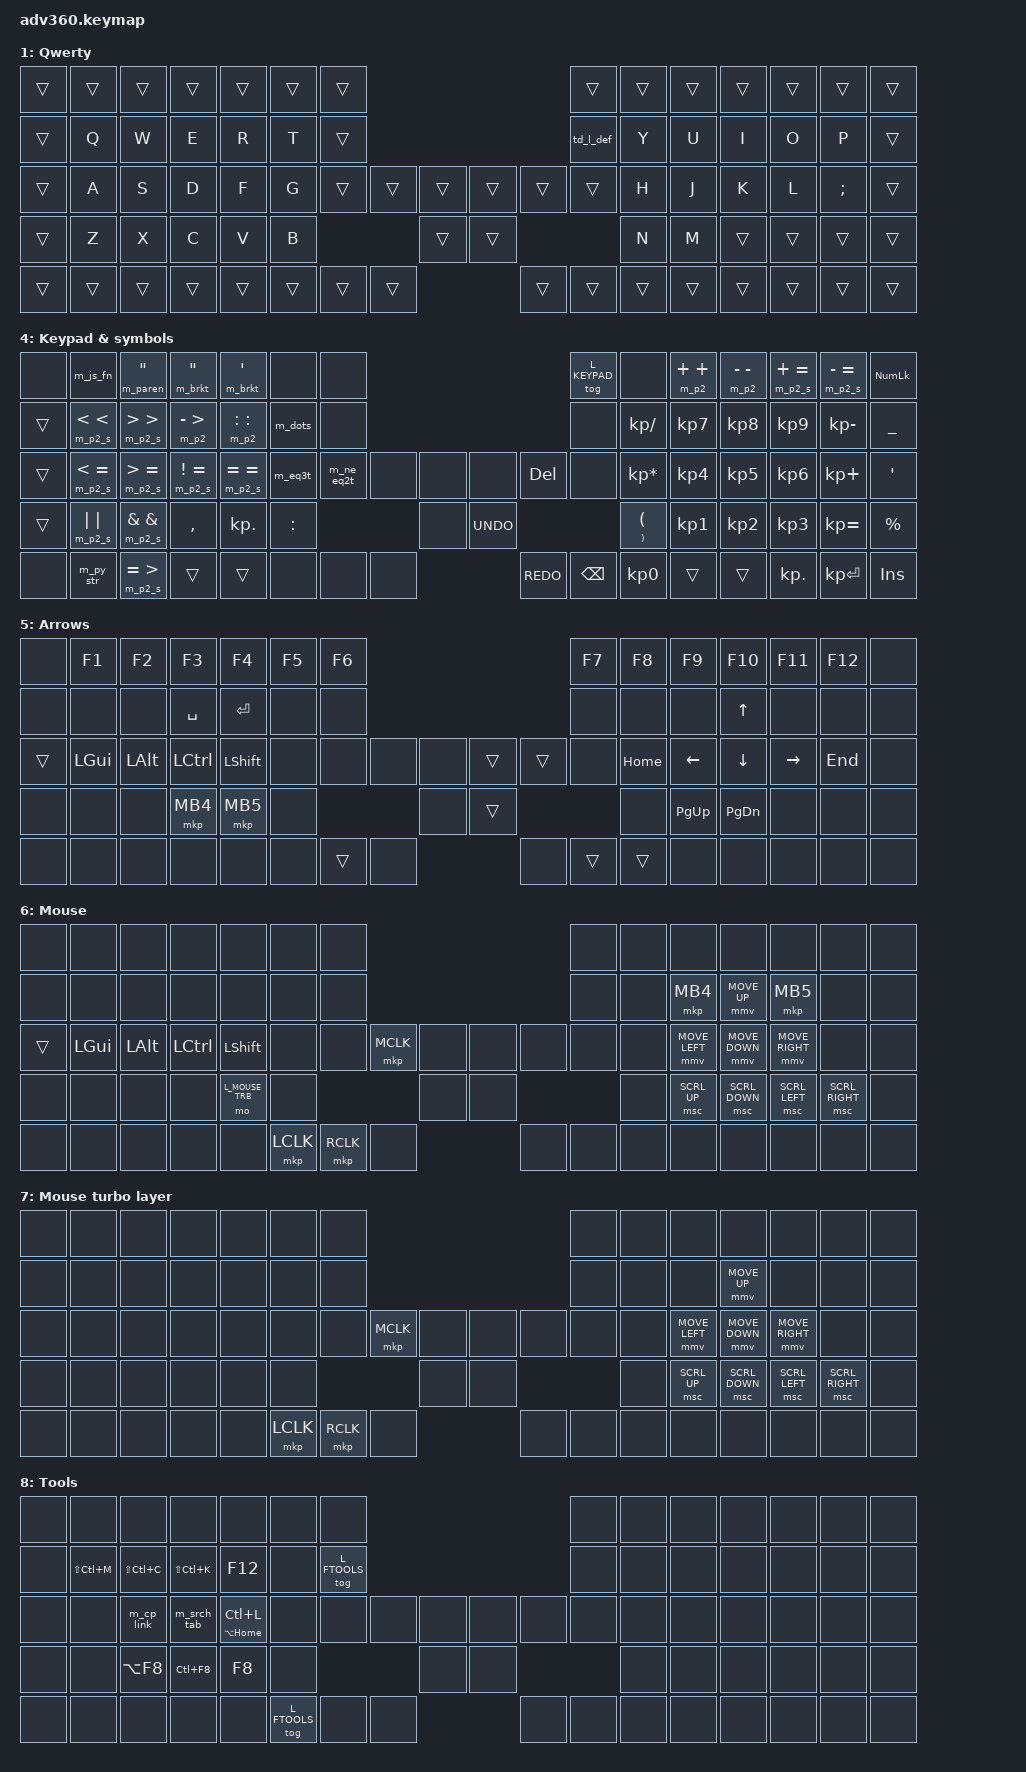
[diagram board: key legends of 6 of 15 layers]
#include <behaviors.dtsi>
#include <dt-bindings/zmk/keys.h>
#include <dt-bindings/zmk/bt.h>
#include <dt-bindings/zmk/rgb.h>
#include <dt-bindings/zmk/stp.h>
#include <dt-bindings/zmk/backlight.h>
#define ZMK_POINTING_DEFAULT_MOVE_VAL 1200 
#define ZMK_POINTING_DEFAULT_SCRL_VAL 20
#include <dt-bindings/zmk/pointing.h>
#include <input/processors.dtsi>

/* PREPROCESSOR */
// Constants
#define TAP_TERM_DEF 180
#define TAP_TERM_MFAST 130
#define TAP_TERM_FAST 150
#define TAP_TERM_SLOW 200
// Layers
#define L_DEFAULT    0
#define L_QWERTY     1
#define L_MAC        2
#define L_MEDIA      3
#define L_KEYPAD     4
#define L_ARROWS     5
#define L_MOUSE      6
#define L_MOUSE_TRB  7
#define L_FTOOLS     8
#define L_FTOOLS_MAC 9
#define L_HYPRLAND   10
#define L_HYPR_GR    11
#define L_AEROSPACE  12
#define L_APPS       13
#define L_EDITOR     14
// Macros
// - tap, hold, double tap
#define TD_A1(NAME, KP) \
    NAME: NAME { \
        compatible = "zmk,behavior-tap-dance"; \
        #binding-cells = <0>; \
        bindings = <&kp KP>; \
    }
#define TD_A1_DT_TOG_LYR(NAME, LAYER) \
    NAME: NAME { \
        compatible = "zmk,behavior-tap-dance"; \
        #binding-cells = <0>; \
        tapping-term-ms = <TAP_TERM_DEF>; \
        bindings = <&none>, <&tog LAYER>; \
    }
#define TD_A1_DT_KP(NAME, KP ) \
    NAME: NAME { \
        compatible = "zmk,behavior-tap-dance"; \
        #binding-cells = <0>; \
        tapping-term-ms = <TAP_TERM_DEF>; \
        bindings = <&none>, <&kp KP>; \
    }
#define TD_A1_DT_TO_LYR(NAME, LAYER) \
    NAME: NAME { \
        compatible = "zmk,behavior-tap-dance"; \
        #binding-cells = <0>; \
        tapping-term-ms = <TAP_TERM_DEF>; \
        bindings = <&none>, <&to LAYER>; \
    }
#define TD_A2(NAME, TAP, D_TAP) \
    NAME: NAME { \
        compatible = "zmk,behavior-tap-dance"; \
        #binding-cells = <0>; \
        tapping-term-ms = <TAP_TERM_DEF>; \
        bindings = <&kp TAP>, <&kp D_TAP>; \
    }
#define TD_A3(NAME, TAP, HOLD, D_TAP) \
    NAME: NAME { \
        compatible = "zmk,behavior-tap-dance"; \
        #binding-cells = <0>; \
        tapping-term-ms = <TAP_TERM_DEF>; \
        bindings = <&ht_dfn_mfst HOLD TAP>, <&kp D_TAP>; \
    }
#define TD_A4(NAME, TAP, HOLD, D_TAP, T_TAP) \
    NAME: NAME { \
        compatible = "zmk,behavior-tap-dance"; \
        #binding-cells = <0>; \
        tapping-term-ms = <TAP_TERM_SLOW>; \
        bindings = <&ht_dfn_mfst HOLD TAP>, <&kp D_TAP>, <&kp T_TAP>; \
    }
#define TD_SL_TOG(NAME, LAYER) \
    NAME: NAME { \
        compatible = "zmk,behavior-tap-dance"; \
        #binding-cells = <0>; \
        tapping-term-ms = <TAP_TERM_DEF>; \
        bindings = <&sl LAYER>, <&tog LAYER>; \
    }

/* DEFAULT BEHAVIORS */
&mt { // Mod-Tap
    tapping-term-ms = <TAP_TERM_DEF>;
};
&lt { // Layer-Tap
    tapping-term-ms = <TAP_TERM_DEF>;
};
&sk { // Sticky key
    release-after-ms = <1000>;
};
&sl { // Sticky layer
    release-after-ms = <1500>;
    /delete-property/ quick-release;
};
&caps_word {
    continue-list = <UNDERSCORE MINUS BACKSPACE DELETE>;
};
&mmv {
    time-to-max-speed-ms = <400>;
    delay-ms = <0>;
};
&msc {
    delay-ms = <0>;
};
/* CONFIG */
/ {
    behaviors {
        // Custom
        esc_ent: mod_morph_escape_enter {
            compatible = "zmk,behavior-mod-morph";
            #binding-cells = <0>;
            bindings = <&kp ESC>, <&kp ENTER>;
            mods = <MOD_LCTL>;
        };
        skq: sticky_key_quick_release {
            compatible = "zmk,behavior-sticky-key";
            #binding-cells = <1>;
            bindings = <&kp>;
            release-after-ms = <1500>;
            quick-release;
            ignore-modifiers;
        };
        hrm: ht_home_row_mods {
            compatible = "zmk,behavior-hold-tap";
            #binding-cells = <2>;
            /* flavor = "balanced"; */
            flavor = "tap-preferred";
            require-prior-idle-ms = <135>;
            tapping-term-ms = <TAP_TERM_DEF>;
            quick-tap-ms = <150>;
            hold-while-undecided;
            retro-tap;
            bindings = <&kp>, <&kp>;
        };
        ht_cl: ht_cluster_layer {
            compatible = "zmk,behavior-hold-tap";
            #binding-cells = <2>;
            flavor = "hold-preferred"; 
            tapping-term-ms = <TAP_TERM_SLOW>;
            quick-tap-ms = <175>;     
            /* retro-tap;           */
            bindings = <&mo>, <&kp>;
        };
        ht_cl_tp: ht_cluster_layer_tap_preferred {
            compatible = "zmk,behavior-hold-tap";
            #binding-cells = <2>;
            flavor = "tap-preferred"; 
            tapping-term-ms = <TAP_TERM_DEF>;
            quick-tap-ms = <TAP_TERM_DEF>;     
            require-prior-idle-ms = <160>;
            retro-tap;          
            bindings = <&mo>, <&kp>;
        };
        test_lp: test_layer_press {
            compatible = "zmk,behavior-hold-tap";
            #binding-cells = <2>;
            flavor = "hold-preferred";
            tapping-term-ms = <200>;
            quick-tap-ms = <175>;      
            retro-tap;                 
            bindings = <&mo>, <&kp>;   
        };
        ht_dfn_mfst: ht_dual_function_mega_fast {
            compatible = "zmk,behavior-hold-tap";
            #binding-cells = <2>;
            flavor = "tap-preferred"; 
            tapping-term-ms = <TAP_TERM_MFAST>;
            bindings = <&kp>, <&kp>;
        };
        ht_mo_sl: ht_momentary_sticky_layer { 
            compatible = "zmk,behavior-hold-tap";
            #binding-cells = <2>;
            flavor = "hold-preferred";
            tapping-term-ms = <TAP_TERM_FAST>;
            bindings = <&mo>, <&sl>; 
        };
        ht_tog_sl: ht_toggle_sticky_layer { 
            compatible = "zmk,behavior-hold-tap";
            #binding-cells = <2>;
            flavor = "hold-preferred";
            tapping-term-ms = <TAP_TERM_FAST>;
            bindings = <&tog>, <&sl>; 
        };
        ht_mo_tog: ht_momentary_toggle_layer { 
            compatible = "zmk,behavior-hold-tap";
            #binding-cells = <2>;
            flavor = "hold-preferred";
            tapping-term-ms = <TAP_TERM_FAST>;
            bindings = <&mo>, <&tog>; 
        };
        cw_caps: caps_word_hold_tap {
            compatible = "zmk,behavior-hold-tap";
            #binding-cells = <2>;
            flavor = "tap-preferred";
            tapping-term-ms = <TAP_TERM_MFAST>;
            quick-tap-ms = <0>;
            bindings = <&kp>, <&caps_word>; 
        };
        // - Keyboard layout (qwerty/mac) switch on hold and double tap 
        to_hold_tap: to_hold_tap {
            compatible = "zmk,behavior-hold-tap";
            #binding-cells = <2>;
            flavor = "tap-preferred";
            tapping-term-ms = <TAP_TERM_DEF>;
            bindings = <&to>, <&none>;
        };
        td_layout: td_change_layout {
            compatible = "zmk,behavior-tap-dance";
            #binding-cells = <0>;
            tapping-term-ms = <TAP_TERM_DEF>;
            bindings = <&to_hold_tap L_MAC 0>, <&to L_QWERTY>; 
        };
        td_bootloader: td_bootloader {
            compatible = "zmk,behavior-tap-dance";
            #binding-cells = <0>;
            tapping-term-ms = <TAP_TERM_DEF>;
            bindings = <&none>, <&bootloader>; 
        };
        td_bt_cl: td_bluetooth_clear {
            compatible = "zmk,behavior-tap-dance";
            #binding-cells = <0>;
            tapping-term-ms = <TAP_TERM_DEF>;
            bindings = <&none>, <&bt BT_CLR>; 
        };
        td_bt_cl_all: td_bluetooth_clear_all {
            compatible = "zmk,behavior-tap-dance";
            #binding-cells = <0>;
            tapping-term-ms = <TAP_TERM_DEF>;
            bindings = <&none>, <&bt BT_CLR_ALL>; 
        };
        // tap-dance
        TD_A1_DT_TOG_LYR(td_keypad, L_KEYPAD); // toggle keypad layer on double tap
        TD_A1_DT_TO_LYR(td_l_def, L_DEFAULT); // toggle default layer on double tap
        TD_A1_DT_KP(td_sleep_lnx, LG(LS(LA(L)))); // sleep system on Linux
        TD_A1_DT_KP(td_sleep_mac, LC(LA(C_EJECT))); // sleep system on MacOS
        TD_A3(td_e_methods, LS(LC(D)), LC(I), LC(O)); // editor, methods
        TD_A3(td_e_refactor, LS(F6), LC(F6), F6); // editor, refactor
        TD_A3(td_e_sur_life, LC(LA(J)), LS(LA(T)), LC(J)); // editor, surround/live template
        TD_A3(td_e_f_expand, LC(EQUAL), LC(LA(EQUAL)), LS(LC(EQUAL))); // editor, fold expand
        TD_A3(td_e_f_collapse, LC(MINUS), LC(LA(MINUS)), LS(LC(MINUS))); // editor, fold collapse
        TD_A3(td_tmac_info, LG(LA(I)), LG(I), LG(J)); // mac, tools, files info
        TD_A4(td_e_bookmarks, LS(LC(LA(RIGHT_BRACKET))), F11, LS(LC(LA(LEFT_BRACKET))), LS(LC(F11))); // editor, bookmarks
        TD_A4(td_a4_h_res, LG(R), LG(LC(R)), LG(LA(R)), LG(LC(LA(R)))); // hyprland, resize window
        TD_A4(td_breakpoint, LC(F8), LS(LC(F8)), LS(LC(F3)), LS(LC(LA(F8)))); // editor, breakpoints
        TD_SL_TOG(td_hypr, L_HYPRLAND); // hyprland layer activation
        TD_SL_TOG(td_aerospace, L_AEROSPACE); // aerospace layer activation
        // macros
        m_pc: macro_switch_to_pc {
            compatible = "zmk,behavior-macro";
            #binding-cells = <0>; 
            bindings =
                <&to L_DEFAULT>,
                <&bt BT_SEL 0>;
        };
        m_mac: macro_switch_to_mac {
            compatible = "zmk,behavior-macro";
            #binding-cells = <0>; 
            bindings =
                <&to L_MAC>,
                <&bt BT_SEL 1>;
        };
        m_p2: macro_two_param {
            compatible = "zmk,behavior-macro-two-param";
            #binding-cells = <2>; 
            bindings =
                <&macro_param_1to1>,
                <&macro_tap &kp MACRO_PLACEHOLDER>,
                <&macro_param_2to1>,
                <&macro_tap &kp MACRO_PLACEHOLDER>;
        };
        m_p2_s: macro_two_param_with_space {
            compatible = "zmk,behavior-macro-two-param";
            #binding-cells = <2>; 
            bindings =
                <&macro_param_1to1>,
                <&macro_tap &kp MACRO_PLACEHOLDER>,
                <&macro_param_2to1>,
                <&macro_tap &kp MACRO_PLACEHOLDER>,
                <&macro_tap &kp SPACE>;
        };
        m_brkt: macro_brackets_left_left {
            compatible = "zmk,behavior-macro-one-param";
            #binding-cells = <1>; 
            bindings =
                <&macro_tap &kp LEFT_BRACKET>,               
                <&macro_param_1to1>,
                <&macro_tap &kp MACRO_PLACEHOLDER>,
                <&macro_param_1to1>,
                <&macro_tap &kp MACRO_PLACEHOLDER>,
                <&macro_tap &kp RIGHT_BRACKET>,
                <&macro_tap &kp LEFT_ARROW &kp LEFT_ARROW>;
        };
        m_paren: macro_parenthesis_left_left {
            compatible = "zmk,behavior-macro-one-param";
            #binding-cells = <1>; 
            bindings =
                <&macro_tap &kp LEFT_PARENTHESIS>,               
                <&macro_param_1to1>,
                <&macro_tap &kp MACRO_PLACEHOLDER>,
                <&macro_param_1to1>,
                <&macro_tap &kp MACRO_PLACEHOLDER>,
                <&macro_tap &kp RIGHT_PARENTHESIS>,
                <&macro_tap &kp LEFT_ARROW &kp LEFT_ARROW>;
        };
        m_js_fn: macro_js_anon_function {
            compatible = "zmk,behavior-macro";
            #binding-cells = <0>; 
            bindings =
                <&macro_tap &kp LEFT_PARENTHESIS &kp RIGHT_PARENTHESIS>,               
                <&macro_tap &kp SPACE &kp EQUAL &kp GREATER_THAN>;
        };
        m_py_str: macro_python_string_param {
            compatible = "zmk,behavior-macro";
            #binding-cells = <0>; 
            bindings =
                <&macro_tap &kp DOLLAR>,
                <&macro_tap &kp LEFT_BRACE &kp RIGHT_BRACE>,
                <&macro_tap &kp LEFT_ARROW>;
        };
        m_dots: macro_triple_dots {
            compatible = "zmk,behavior-macro";
            #binding-cells = <0>; 
            bindings = <&macro_tap &kp DOT &kp DOT &kp DOT>;
        };
        m_eq3t: macro_eq_eq_eq {
            compatible = "zmk,behavior-macro";
            #binding-cells = <0>; 
            bindings = <&macro_tap &kp EQUAL &kp EQUAL &kp EQUAL &kp SPACE>;
        };
        m_ne_eq2t: macro_ne_eq_eq {
            compatible = "zmk,behavior-macro";
            #binding-cells = <0>; 
            bindings = <&macro_tap &kp EXCL &kp EQUAL &kp EQUAL &kp SPACE>;
        };
        m_cp_link: macro_copy_link {
            compatible = "zmk,behavior-macro";
            #binding-cells = <0>; 
            bindings = <&macro_tap &kp LC(L) &kp LC(C) &kp ESC &kp ESC>;
        };
        m_cp_link_m: macro_copy_link_mac {
            compatible = "zmk,behavior-macro";
            #binding-cells = <0>; 
            bindings = <&macro_tap &kp LC(L) &kp LG(C) &kp ESC &kp ESC>;
        };
        m_srch_tab: macro_search_tab {
            compatible = "zmk,behavior-macro";
            #binding-cells = <0>; 
            bindings = <&macro_tap &kp LC(L) &kp PERCENT &kp SPACE>;
        };
    };

  /* KEYMAP */
  keymap {
    compatible = "zmk,keymap";
    default_layer { 
      display-name = "Base";
      bindings = <
  &kp GRAVE    &kp N1     &kp N2            &kp N3     &kp N4      &kp N5   &kp PSCRN                                                                                                                                                                 &td_keypad   &kp N6   &kp N7   &kp N8      &kp N9     &kp N0     &kp EQUAL
  &kp TAB      &kp Q      &kp W             &kp F      &kp P       &kp B    &ht_tog_sl L_FTOOLS L_FTOOLS                                                                                                                                              &td_layout   &kp J    &kp L    &kp U       &kp Y      &kp SEMI   &kp MINUS
  &kp ESC      &kp A      &kp R             &kp S      &kp T       &kp G    &ht_dfn_mfst LG(LC(LA(LEFT))) LG(LC(LA(RIGHT)))                          &kp LCTRL             &kp LALT   &sk LALT      &sk RCTRL                                         &none        &kp M    &kp N    &kp E       &kp I      &kp O      &kp SQT
  &kp LSHFT    &kp Z      &kp X             &kp C      &kp D       &kp V                                                                                                   &kp LGUI   &sk RGUI                                                                     &kp K    &kp H    &kp COMMA   &kp DOT    &kp FSLH   &kp RSHFT
  &sl L_APPS   &kp BSLH   &cw_caps CAPS 0   &kp LEFT   &kp RIGHT                                                              &ht_cl L_ARROWS BSPC   &ht_cl L_KEYPAD DEL   &td_hypr   &mo L_MEDIA   &ht_cl L_EDITOR ENTER   &ht_cl_tp L_MOUSE SPACE                         &kp UP   &kp DOWN    &kp LBKT   &kp RBKT   &ht_dfn_mfst LG(LC(L)) LG(LS(L))
//    ┌─────────┬───┬──────────┬──────┬──────┬───┬──────────────┐                                                                                  ┌───────────────┬───┬────┬──────┬───┬───┬──────┐
//    │    `    │ 1 │    2     │  3   │  4   │ 5 │     pscr     │                                                                                  │  tog Keypad   │ 6 │ 7  │  8   │ 9 │ 0 │  =   │
//    ├─────────┼───┼──────────┼──────┼──────┼───┼──────────────┤                                                                                  ├───────────────┼───┼────┼──────┼───┼───┼──────┤
//    │   tab   │ Q │    W     │  F   │  P   │ B │ tog sl Tools │                                                                                  │ to Qwerty/Mac │ J │ L  │  U   │ Y │ ; │  -   │
//    ├─────────┼───┼──────────┼──────┼──────┼───┼──────────────┤             ┌────────────┬─────────────┬────────────┬──────────────┐             ├───────────────┼───┼────┼──────┼───┼───┼──────┤
//    │   esc   │ A │    R     │  S   │  T   │ G │  < worksp >  │             │    lctl    │    lalt     │  &sk lalt  │   &sk rctl   │             │               │ M │ N  │  E   │ I │ O │  '   │
//    ├─────────┼───┼──────────┼──────┼──────┼───┼──────────────┘             └────────────┼─────────────┼────────────┼──────────────┘             └───────────────┼───┼────┼──────┼───┼───┼──────┤
//    │  lsft   │ Z │    X     │  C   │  D   │ V │                                         │    lgui     │  &sk rgui  │                                            │ K │ H  │  ,   │ . │ / │ rsft │
//    ├─────────┼───┼──────────┼──────┼──────┼───┘              ┌─────────────┬────────────┼─────────────┼────────────┼──────────────┬─────────────┐               └───┼────┼──────┼───┼───┼──────┤
//    │ sl Apps │ \ │ caps duo │ left │ rght │                  │ bspc/Arrows │ del/Keypad │ td Hyprland │ mo L_MEDIA │ enter/Editor │ space/Mouse │                   │ up │ down │ [ │ ] │ lang │
//    └─────────┴───┴──────────┴──────┴──────┘                  └─────────────┴────────────┴─────────────┴────────────┴──────────────┴─────────────┘                   └────┴──────┴───┴───┴──────┘
      >;
    };
    qwerty { 
      display-name = "Qwerty";
      bindings = <
  &trans   &trans   &trans   &trans   &trans   &trans   &trans                                                         &trans      &trans   &trans   &trans   &trans   &trans     &trans
  &trans   &kp Q    &kp W    &kp E    &kp R    &kp T    &trans                                                         &td_l_def   &kp Y    &kp U    &kp I    &kp O    &kp P      &trans
  &trans   &kp A    &kp S    &kp D    &kp F    &kp G    &trans            &trans   &trans   &trans   &trans            &trans      &kp H    &kp J    &kp K    &kp L    &kp SEMI   &trans
  &trans   &kp Z    &kp X    &kp C    &kp V    &kp B                               &trans   &trans                                 &kp N    &kp M    &trans   &trans   &trans     &trans
  &trans   &trans   &trans   &trans   &trans                     &trans   &trans   &trans   &trans   &trans   &trans                        &trans   &trans   &trans   &trans     &trans
//    ┌───┬───┬───┬───┬───┬───┬───┐                       ┌────────────┬───┬───┬───┬───┬───┬───┐
//    │ & │ & │ & │ & │ & │ & │ & │                       │     &      │ & │ & │ & │ & │ & │ & │
//    ├───┼───┼───┼───┼───┼───┼───┤                       ├────────────┼───┼───┼───┼───┼───┼───┤
//    │ & │ Q │ W │ E │ R │ T │ & │                       │ to Default │ Y │ U │ I │ O │ P │ & │
//    ├───┼───┼───┼───┼───┼───┼───┤   ┌───┬───┬───┬───┐   ├────────────┼───┼───┼───┼───┼───┼───┤
//    │ & │ A │ S │ D │ F │ G │ & │   │ & │ & │ & │ & │   │     &      │ H │ J │ K │ L │ ; │ & │
//    ├───┼───┼───┼───┼───┼───┼───┘   └───┼───┼───┼───┘   └────────────┼───┼───┼───┼───┼───┼───┤
//    │ & │ Z │ X │ C │ V │ B │           │ & │ & │                    │ N │ M │ & │ & │ & │ & │
//    ├───┼───┼───┼───┼───┼───┘   ┌───┬───┼───┼───┼───┬───┐            └───┼───┼───┼───┼───┼───┤
//    │ & │ & │ & │ & │ & │       │ & │ & │ & │ & │ & │ & │                │ & │ & │ & │ & │ & │
//    └───┴───┴───┴───┴───┘       └───┴───┴───┴───┴───┴───┘                └───┴───┴───┴───┴───┘
      >;
    };
    mac { 
      display-name = "MacOS";
      bindings = <
  &trans    &trans   &trans   &trans   &trans   &trans   &ht_dfn_mfst LG(LS(N3)) LG(LS(N4))                                                                             &trans          &trans   &trans   &trans   &trans   &trans   &trans
  &trans    &trans   &trans   &trans   &trans   &trans   &ht_tog_sl L_FTOOLS_MAC L_FTOOLS_MAC                                                                           &td_l_def       &trans   &trans   &trans   &trans   &trans   &trans
  &kp ESC   &trans   &trans   &trans   &trans   &trans   &ht_dfn_mfst LG(LS(LC(W))) LG(LC(LA(W)))            &sk LGUI   &trans          &trans      &sk RGUI            &kp LC(SPACE)   &trans   &trans   &trans   &trans   &trans   &trans
  &trans    &trans   &trans   &trans   &trans   &trans                                                                  &sk LCTRL       &sk RCTRL                                       &trans   &trans   &trans   &trans   &trans   &trans
  &trans    &trans   &trans   &trans   &trans                                                       &trans   &trans     &td_aerospace   &trans      &trans     &trans                            &trans   &trans   &trans   &trans   &kp LG(SPACE)
//    ┌─────┬───┬───┬───┬───┬───┬──────────────────┐                                                       ┌────────────┬───┬───┬───┬───┬───┬──────┐
//    │  &  │ & │ & │ & │ & │ & │    screenshot    │                                                       │     &      │ & │ & │ & │ & │ & │  &   │
//    ├─────┼───┼───┼───┼───┼───┼──────────────────┤                                                       ├────────────┼───┼───┼───┼───┼───┼──────┤
//    │  &  │ & │ & │ & │ & │ & │ tog sl Tools mac │                                                       │ to Default │ & │ & │ & │ & │ & │  &   │
//    ├─────┼───┼───┼───┼───┼───┼──────────────────┤   ┌──────────┬──────────────┬──────────┬──────────┐   ├────────────┼───┼───┼───┼───┼───┼──────┤
//    │ esc │ & │ & │ & │ & │ & │    < worksp >    │   │ &sk lgui │      &       │    &     │ &sk rgui │   │   search   │ & │ & │ & │ & │ & │  &   │
//    ├─────┼───┼───┼───┼───┼───┼──────────────────┘   └──────────┼──────────────┼──────────┼──────────┘   └────────────┼───┼───┼───┼───┼───┼──────┤
//    │  &  │ & │ & │ & │ & │ & │                                 │   &sk lctl   │ &sk rctl │                           │ & │ & │ & │ & │ & │  &   │
//    ├─────┼───┼───┼───┼───┼───┘                  ┌───┬──────────┼──────────────┼──────────┼──────────┬───┐            └───┼───┼───┼───┼───┼──────┤
//    │  &  │ & │ & │ & │ & │                      │ & │    &     │ td Aerospace │    &     │    &     │ & │                │ & │ & │ & │ & │ lang │
//    └─────┴───┴───┴───┴───┘                      └───┴──────────┴──────────────┴──────────┴──────────┴───┘                └───┴───┴───┴───┴──────┘
      >;
    };
    media { 
      display-name = "Media";
      bindings = <
  &none            &m_pc   &m_mac          &bt BT_SEL 2   &bt BT_SEL 3    &bt BT_SEL 4   &none                                                                                     &none           &none                   &none                   &none               &none               &none   &td_bt_cl
  &none            &none   &none           &none          &none           &none          &none                                                                                     &td_sleep_mac   &kp LG(LC(Q))           &kp LG(LS(LC(LA(O))))   &kp LG(LS(LA(O)))   &kp LG(LS(LC(O)))   &none   &td_bt_cl_all
  &studio_unlock   &none   &kp C_BRI_DEC   &none          &kp C_BRI_INC   &none          &none                &bl BL_TOG   &rgb_ug RGB_TOG   &none   &none                         &td_sleep_lnx   &kp LG(LS(LC(LA(L))))   &kp C_VOL_DN            &kp C_MUTE          &kp C_VOL_UP        &none   &none
  &stp STP_BAT     &none   &none           &none          &none           &none                                            &none             &none                                                 &none                   &kp C_PREV              &kp C_PLAY_PAUSE    &kp C_NEXT          &none   &none
  &td_bootloader   &none   &none           &none          &none                                  &bl BL_DEC   &bl BL_INC   &none             &none   &kp C_VOL_DN   &kp C_VOL_UP                                           &none                   &none               &none               &none   &td_bootloader
//    ┌────────────────┬───────┬────────┬──────────┬──────────┬──────────┬─────┐                                                 ┌───────────────┬──────────┬──────────┬────────────┬──────┬─────┬────────────────┐
//    │                │ &m_pc │ &m_mac │ bt_sel 2 │ bt_sel 3 │ bt_sel 4 │     │                                                 │               │          │          │            │      │     │   &td_bt_cl    │
//    ├────────────────┼───────┼────────┼──────────┼──────────┼──────────┼─────┤                                                 ├───────────────┼──────────┼──────────┼────────────┼──────┼─────┼────────────────┤
//    │                │       │        │          │          │          │     │                                                 │ &td_sleep_mac │ lock mac │ speakers │ headphones │ hdmi │     │ &td_bt_cl_all  │
//    ├────────────────┼───────┼────────┼──────────┼──────────┼──────────┼─────┤         ┌─────────┬─────────┬─────┬──────┐      ├───────────────┼──────────┼──────────┼────────────┼──────┼─────┼────────────────┤
//    │ &studio_unlock │       │  bri-  │          │   bri+   │          │     │         │ bl_ tog │ ug_ tog │     │      │      │ &td_sleep_lnx │   lock   │   vold   │    mute    │ volu │     │                │
//    ├────────────────┼───────┼────────┼──────────┼──────────┼──────────┼─────┘         └─────────┼─────────┼─────┼──────┘      └───────────────┼──────────┼──────────┼────────────┼──────┼─────┼────────────────┤
//    │    bat lvl     │       │        │          │          │          │                         │         │     │                             │          │   prev   │    play    │ next │     │                │
//    ├────────────────┼───────┼────────┼──────────┼──────────┼──────────┘     ┌─────────┬─────────┼─────────┼─────┼──────┬──────┐               └──────────┼──────────┼────────────┼──────┼─────┼────────────────┤
//    │ &td_bootloader │       │        │          │          │                │ bl_ br- │ bl_ br+ │         │     │ vold │ volu │                          │          │            │      │     │ &td_bootloader │
//    └────────────────┴───────┴────────┴──────────┴──────────┘                └─────────┴─────────┴─────────┴─────┴──────┴──────┘                          └──────────┴────────────┴──────┴─────┴────────────────┘
      >;
    };
    keypad { 
      display-name = "Keypad & symbols";
      bindings = <
  &none    &m_js_fn            &m_paren DOUBLE_QUOTES   &m_brkt DOUBLE_QUOTES   &m_brkt SINGLE_QUOTE   &none       &none                                                                         &tog L_KEYPAD   &none                    &m_p2 PLUS PLUS   &m_p2 MINUS MINUS   &m_p2_s PLUS EQUAL   &m_p2_s MINUS EQUAL   &kp KP_NUMLOCK
  &trans   &m_p2_s LT LT       &m_p2_s GT GT            &m_p2 MINUS GT          &m_p2 COLON COLON      &m_dots     &none                                                                         &none           &kp KP_DIVIDE            &kp KP_N7         &kp KP_N8           &kp KP_N9            &kp KP_MINUS          &kp UNDERSCORE
  &trans   &m_p2_s LT EQUAL    &m_p2_s GT EQUAL         &m_p2_s EXCL EQUAL      &m_p2_s EQUAL EQUAL    &m_eq3t     &m_ne_eq2t           &none   &none   &none        &kp DEL                     &none           &kp KP_MULTIPLY          &kp KP_N4         &kp KP_N5           &kp KP_N6            &kp KP_PLUS           &kp SQT
  &trans   &m_p2_s PIPE PIPE   &m_p2_s AMPS AMPS        &kp COMMA               &kp KP_DOT             &kp COLON                                &none   &kp K_UNDO                                               &ht_dfn_mfst RPAR LPAR   &kp KP_N1         &kp KP_N2           &kp KP_N3            &kp KP_EQUAL          &kp PERCENT
  &none    &m_py_str           &m_p2_s EQUAL GT         &trans                  &trans                                          &none   &none   &none   &kp K_REDO   &kp BACKSPACE   &kp KP_N0                                            &trans            &trans              &kp KP_DOT           &kp KP_ENTER          &kp INSERT
//    ┌─────┬──────┬──────┬──────┬──────┬─────┬─────┐                                    ┌────────────┬─────┬────┬────┬────┬─────┬──────┐
//    │     │ ()=> │ ("") │ [""] │ [''] │     │     │                                    │ tog Keypad │     │ ++ │ -- │ += │ -=  │ nlck │
//    ├─────┼──────┼──────┼──────┼──────┼─────┼─────┤                                    ├────────────┼─────┼────┼────┼────┼─────┼──────┤
//    │  &  │  <<  │  >>  │  ->  │  ::  │ ... │     │                                    │            │  /  │ 7  │ 8  │ 9  │  -  │  _   │
//    ├─────┼──────┼──────┼──────┼──────┼─────┼─────┤     ┌─────┬─────┬───────┬──────┐   ├────────────┼─────┼────┼────┼────┼─────┼──────┤
//    │  &  │  <=  │  >=  │  !=  │  ==  │ === │ !== │     │     │     │       │ del  │   │            │  *  │ 4  │ 5  │ 6  │  +  │  '   │
//    ├─────┼──────┼──────┼──────┼──────┼─────┼─────┘     └─────┼─────┼───────┼──────┘   └────────────┼─────┼────┼────┼────┼─────┼──────┤
//    │  &  │  ||  │  &&  │  ,   │  .   │  :  │                 │     │ undo  │                       │ ()  │ 1  │ 2  │ 3  │  =  │  %   │
//    ├─────┼──────┼──────┼──────┼──────┼─────┘     ┌─────┬─────┼─────┼───────┼──────┬───┐            └─────┼────┼────┼────┼─────┼──────┤
//    │     │ ${}  │  =>  │  &   │  &   │           │     │     │     │ again │ bspc │ 0 │                  │ &  │ &  │ .  │ ent │ ins  │
//    └─────┴──────┴──────┴──────┴──────┘           └─────┴─────┴─────┴───────┴──────┴───┘                  └────┴────┴────┴─────┴──────┘
      >;
    };
    arrows { 
      display-name = "Arrows";
      bindings = <
  &none    &kp F1     &kp F2     &kp F3      &kp F4       &kp F5   &kp F6                                                       &kp F7   &kp F8     &kp F9      &kp F10     &kp F11     &kp F12   &none
  &none    &none      &none      &kp SPACE   &kp ENTER    &none    &none                                                        &none    &none      &none       &kp UP      &none       &none     &none
  &trans   &kp LGUI   &kp LALT   &kp LCTRL   &kp LSHIFT   &none    &none            &none    &none   &trans   &trans            &none    &kp HOME   &kp LEFT    &kp DOWN    &kp RIGHT   &kp END   &none
  &none    &none      &none      &mkp MB4    &mkp MB5     &none                              &none   &trans                              &none      &kp PG_UP   &kp PG_DN   &none       &none     &none
  &none    &none      &none      &none       &none                          &none   &trans   &none   &none    &trans   &trans                       &none       &none       &none       &none     &none
//    ┌─────┬──────┬──────┬──────┬──────┬─────┬─────┐                               ┌─────┬──────┬──────┬──────┬──────┬─────┬─────┐
//    │     │  f1  │  f2  │  f3  │  f4  │ f5  │ f6  │                               │ f7  │  f8  │  f9  │ f10  │ f11  │ f12 │     │
//    ├─────┼──────┼──────┼──────┼──────┼─────┼─────┤                               ├─────┼──────┼──────┼──────┼──────┼─────┼─────┤
//    │     │      │      │ spc  │ ent  │     │     │                               │     │      │      │  up  │      │     │     │
//    ├─────┼──────┼──────┼──────┼──────┼─────┼─────┤     ┌─────┬─────┬─────┬───┐   ├─────┼──────┼──────┼──────┼──────┼─────┼─────┤
//    │  &  │ lgui │ lalt │ lctl │ lsft │     │     │     │     │     │  &  │ & │   │     │ home │ left │ down │ rght │ end │     │
//    ├─────┼──────┼──────┼──────┼──────┼─────┼─────┘     └─────┼─────┼─────┼───┘   └─────┼──────┼──────┼──────┼──────┼─────┼─────┤
//    │     │      │      │ mbck │ mfwd │     │                 │     │  &  │             │      │ pgup │ pgdn │      │     │     │
//    ├─────┼──────┼──────┼──────┼──────┼─────┘     ┌─────┬─────┼─────┼─────┼───┬───┐     └──────┼──────┼──────┼──────┼─────┼─────┤
//    │     │      │      │      │      │           │     │  &  │     │     │ & │ & │            │      │      │      │     │     │
//    └─────┴──────┴──────┴──────┴──────┘           └─────┴─────┴─────┴─────┴───┴───┘            └──────┴──────┴──────┴─────┴─────┘
      >;
    };
    mouse { 
    // TODO: maybe remove mb4 and mb5 buttons 
      display-name = "Mouse";
      bindings = <
  &none    &none      &none      &none       &none             &none   &none                                                           &none   &none   &none            &none            &none             &none             &none
  &none    &none      &none      &none       &none             &none   &none                                                           &none   &none   &mkp MB4         &mmv MOVE_UP     &mkp MB5          &none             &none
  &trans   &kp LGUI   &kp LALT   &kp LCTRL   &kp LSHIFT        &none   &none               &mkp MCLK   &none   &none   &none           &none   &none   &mmv MOVE_LEFT   &mmv MOVE_DOWN   &mmv MOVE_RIGHT   &none             &none
  &none    &none      &none      &none       &mo L_MOUSE_TRB   &none                                   &none   &none                           &none   &msc SCRL_UP     &msc SCRL_DOWN   &msc SCRL_LEFT    &msc SCRL_RIGHT   &none
  &none    &none      &none      &none       &none                             &mkp LCLK   &mkp RCLK   &none   &none   &none   &none                   &none            &none            &none             &none             &none
//    ┌─────┬──────┬──────┬──────┬────────────────┬─────┬─────┐                                     ┌─────┬─────┬────────────┬────────────┬─────────────┬────────────────┬─────┐
//    │     │      │      │      │                │     │     │                                     │     │     │            │            │             │                │     │
//    ├─────┼──────┼──────┼──────┼────────────────┼─────┼─────┤                                     ├─────┼─────┼────────────┼────────────┼─────────────┼────────────────┼─────┤
//    │     │      │      │      │                │     │     │                                     │     │     │    mbck    │  mouse up  │    mfwd     │                │     │
//    ├─────┼──────┼──────┼──────┼────────────────┼─────┼─────┤      ┌──────┬─────┬─────┬─────┐     ├─────┼─────┼────────────┼────────────┼─────────────┼────────────────┼─────┤
//    │  &  │ lgui │ lalt │ lctl │      lsft      │     │     │      │ mclk │     │     │     │     │     │     │ mouse left │ mouse down │ mouse right │                │     │
//    ├─────┼──────┼──────┼──────┼────────────────┼─────┼─────┘      └──────┼─────┼─────┼─────┘     └─────┼─────┼────────────┼────────────┼─────────────┼────────────────┼─────┤
//    │     │      │      │      │ mo L_MOUSE_TRB │     │                   │     │     │                 │     │  scrl up   │ scrl down  │  scrl left  │ &msc SCRL_rght │     │
//    ├─────┼──────┼──────┼──────┼────────────────┼─────┘     ┌──────┬──────┼─────┼─────┼─────┬─────┐     └─────┼────────────┼────────────┼─────────────┼────────────────┼─────┤
//    │     │      │      │      │                │           │ lclk │ rclk │     │     │     │     │           │            │            │             │                │     │
//    └─────┴──────┴──────┴──────┴────────────────┘           └──────┴──────┴─────┴─────┴─────┴─────┘           └────────────┴────────────┴─────────────┴────────────────┴─────┘
      >;
    };
    mouse_turbo { 
      display-name = "Mouse turbo layer";
      bindings = <
  &none   &none   &none   &none   &none   &none   &none                                                           &none   &none   &none            &none            &none             &none             &none
  &none   &none   &none   &none   &none   &none   &none                                                           &none   &none   &none            &mmv MOVE_UP     &none             &none             &none
  &none   &none   &none   &none   &none   &none   &none               &mkp MCLK   &none   &none   &none           &none   &none   &mmv MOVE_LEFT   &mmv MOVE_DOWN   &mmv MOVE_RIGHT   &none             &none
  &none   &none   &none   &none   &none   &none                                   &none   &none                           &none   &msc SCRL_UP     &msc SCRL_DOWN   &msc SCRL_LEFT    &msc SCRL_RIGHT   &none
  &none   &none   &none   &none   &none                   &mkp LCLK   &mkp RCLK   &none   &none   &none   &none                   &none            &none            &none             &none             &none
//    ┌─────┬─────┬─────┬─────┬─────┬─────┬─────┐                                     ┌─────┬─────┬────────────┬────────────┬─────────────┬────────────────┬─────┐
//    │     │     │     │     │     │     │     │                                     │     │     │            │            │             │                │     │
//    ├─────┼─────┼─────┼─────┼─────┼─────┼─────┤                                     ├─────┼─────┼────────────┼────────────┼─────────────┼────────────────┼─────┤
//    │     │     │     │     │     │     │     │                                     │     │     │            │  mouse up  │             │                │     │
//    ├─────┼─────┼─────┼─────┼─────┼─────┼─────┤      ┌──────┬─────┬─────┬─────┐     ├─────┼─────┼────────────┼────────────┼─────────────┼────────────────┼─────┤
//    │     │     │     │     │     │     │     │      │ mclk │     │     │     │     │     │     │ mouse left │ mouse down │ mouse right │                │     │
//    ├─────┼─────┼─────┼─────┼─────┼─────┼─────┘      └──────┼─────┼─────┼─────┘     └─────┼─────┼────────────┼────────────┼─────────────┼────────────────┼─────┤
//    │     │     │     │     │     │     │                   │     │     │                 │     │  scrl up   │ scrl down  │  scrl left  │ &msc SCRL_rght │     │
//    ├─────┼─────┼─────┼─────┼─────┼─────┘     ┌──────┬──────┼─────┼─────┼─────┬─────┐     └─────┼────────────┼────────────┼─────────────┼────────────────┼─────┤
//    │     │     │     │     │     │           │ lclk │ rclk │     │     │     │     │           │            │            │             │                │     │
//    └─────┴─────┴─────┴─────┴─────┘           └──────┴──────┴─────┴─────┴─────┴─────┘           └────────────┴────────────┴─────────────┴────────────────┴─────┘
      >;
    };
    tools { 
      display-name = "Tools";
      bindings = <
  &none   &none           &none           &none           &none                         &none   &none                                                                   &none   &none   &none   &none   &none   &none   &none
  &none   &kp LS(LC(M))   &kp LS(LC(C))   &kp LS(LC(K))   &kp F12                       &none   &tog L_FTOOLS                                                           &none   &none   &none   &none   &none   &none   &none
  &none   &none           &m_cp_link      &m_srch_tab     &ht_dfn_mfst LA(HOME) LC(L)   &none   &none                           &none   &none   &none   &none           &none   &none   &none   &none   &none   &none   &none
  &none   &none           &kp LA(F8)      &kp LC(F8)      &kp F8                        &none                                           &none   &none                           &none   &none   &none   &none   &none   &none
  &none   &none           &none           &none           &none                                                 &tog L_FTOOLS   &none   &none   &none   &none   &none                   &none   &none   &none   &none   &none
//    ┌─────┬───────────────┬────────────┬──────────────┬─────────────┬─────┬───────────┐                                         ┌─────┬─────┬─────┬─────┬─────┬─────┬─────┐
//    │     │               │            │              │             │     │           │                                         │     │     │     │     │     │     │     │
//    ├─────┼───────────────┼────────────┼──────────────┼─────────────┼─────┼───────────┤                                         ├─────┼─────┼─────┼─────┼─────┼─────┼─────┤
//    │     │ match bracket │   picker   │   console    │     f12     │     │ tog Tools │                                         │     │     │     │     │     │     │     │
//    ├─────┼───────────────┼────────────┼──────────────┼─────────────┼─────┼───────────┤           ┌─────┬─────┬─────┬─────┐     ├─────┼─────┼─────┼─────┼─────┼─────┼─────┤
//    │     │               │ copy link  │  search tab  │ search/home │     │           │           │     │     │     │     │     │     │     │     │     │     │     │     │
//    ├─────┼───────────────┼────────────┼──────────────┼─────────────┼─────┼───────────┘           └─────┼─────┼─────┼─────┘     └─────┼─────┼─────┼─────┼─────┼─────┼─────┤
//    │     │               │ tabge move │ tabgr manage │     f8      │     │                             │     │     │                 │     │     │     │     │     │     │
//    ├─────┼───────────────┼────────────┼──────────────┼─────────────┼─────┘           ┌───────────┬─────┼─────┼─────┼─────┬─────┐     └─────┼─────┼─────┼─────┼─────┼─────┤
//    │     │               │            │              │             │                 │ tog Tools │     │     │     │     │     │           │     │     │     │     │     │
//    └─────┴───────────────┴────────────┴──────────────┴─────────────┘                 └───────────┴─────┴─────┴─────┴─────┴─────┘           └─────┴─────┴─────┴─────┴─────┘
      >;
    };
    tools_mac { 
      display-name = "Tools MAC";    
      bindings = <
  &kp F16        &none           &none           &none           &none                                  &none                          &none                                                                           &none   &none   &none   &none   &none   &none   &none
  &kp F11        &kp LG(LC(R))   &kp LG(LS(C))   &kp LG(LA(C))   &kp LG(LA(I))                          &ht_dfn_mfst LG(K) LG(LS(G))   &tog L_FTOOLS_MAC                                                               &none   &none   &none   &none   &none   &none   &none
  &kp LC(UP)     &none           &m_cp_link_m    &none           &ht_dfn_mfst LG(L) LG(LS(LC(LA(H))))   &td_tmac_info                  &none                                   &none   &none   &none   &none           &none   &none   &none   &none   &none   &none   &none
  &kp LC(DOWN)   &none           &none           &none           &none                                  &none                                                                          &none   &none                           &none   &none   &none   &none   &none   &none
  &kp F17        &kp F18         &none           &none           &none                                                                                     &tog L_FTOOLS_MAC   &none   &none   &none   &none   &none                   &none   &none   &none   &none   &none
//    ┌──────────────┬───────────────┬───────────┬───────────┬─────────────┬─────────────┬───────────────┐                                             ┌─────┬─────┬─────┬─────┬─────┬─────┬─────┐
//    │  launchpad   │               │           │           │             │             │               │                                             │     │     │     │     │     │     │     │
//    ├──────────────┼───────────────┼───────────┼───────────┼─────────────┼─────────────┼───────────────┤                                             ├─────┼─────┼─────┼─────┼─────┼─────┼─────┤
//    │     f11      │  responsive   │ col res + │ col res - │  dev tools  │ goto/server │ tog Tools mac │                                             │     │     │     │     │     │     │     │
//    ├──────────────┼───────────────┼───────────┼───────────┼─────────────┼─────────────┼───────────────┤               ┌─────┬─────┬─────┬─────┐     ├─────┼─────┼─────┼─────┼─────┼─────┼─────┤
//    │ mission ctrl │               │ copy link │           │ search/home │    info     │               │               │     │     │     │     │     │     │     │     │     │     │     │     │
//    ├──────────────┼───────────────┼───────────┼───────────┼─────────────┼─────────────┼───────────────┘               └─────┼─────┼─────┼─────┘     └─────┼─────┼─────┼─────┼─────┼─────┼─────┤
//    │ app windows  │               │           │           │             │             │                                     │     │     │                 │     │     │     │     │     │     │
//    ├──────────────┼───────────────┼───────────┼───────────┼─────────────┼─────────────┘               ┌───────────────┬─────┼─────┼─────┼─────┬─────┐     └─────┼─────┼─────┼─────┼─────┼─────┤
//    │   postanov   │ notifications │           │           │             │                             │ tog Tools mac │     │     │     │     │     │           │     │     │     │     │     │
//    └──────────────┴───────────────┴───────────┴───────────┴─────────────┘                             └───────────────┴─────┴─────┴─────┴─────┴─────┘           └─────┴─────┴─────┴─────┴─────┘
      >;
    };
    hyprland { 
      display-name = "Hyprland";
      bindings = <
  &none                              &kp LG(N1)               &kp LG(N2)               &kp LG(N3)      &kp LG(N4)          &kp LG(N5)                       &kp LG(N6)                                                                                                             &none                              &none           &kp LG(N7)      &kp LG(N8)      &kp LG(N9)      &kp LG(N0)   &none
  &none                              &none                    &sk LS(LALT)             &kp LG(UP)      &kt LS(LCTRL)       &kp LG(LA(U))                    &ht_dfn_mfst LG(LS(A)) LG(A)                                                                                           &ht_dfn_mfst LG(LS(Y)) LG(LC(Y))   &kp LG(EQUAL)   &kp LG(KP_N7)   &kp LG(KP_N8)   &kp LG(KP_N9)   &none        &none
  &ht_dfn_mfst LG(J) LG(LC(J))       &none                    &kp LG(LEFT)             &kp LG(DOWN)    &kp LG(RIGHT)       &ht_mo_tog L_HYPR_GR L_HYPR_GR   &kp LG(LS(K))                                    &trans   &trans   &trans          &trans                              &ht_dfn_mfst LG(LA(Y)) LG(Y)       &kp LG(RBKT)    &kp LG(KP_N4)   &kp LG(KP_N5)   &kp LG(KP_N6)   &none        &none
  &ht_dfn_mfst LG(LA(J)) LG(LS(J))   &none                    &td_a4_h_res             &kp LG(LA(S))   &kp LG(LC(LA(H)))   &ht_dfn_mfst LG(LC(C)) LG(C)                                                               &none    &kp LG(LS(C))                                                                          &kp LG(LBKT)    &kp LG(KP_N1)   &kp LG(KP_N2)   &kp LG(KP_N3)   &none        &trans
  &kp LG(LA(M))                      &kp LG(LS(LC(LA(N1))))   &kp LG(LS(LC(LA(N2))))   &none           &none                                                                               &tog L_HYPRLAND   &none    &none    &kp LG(LA(C))   &kp LG(LC(LA(C)))   &kp LG(KP_N0)                                                      &none           &none           &none           &none        &none
//    ┌──────────┬───────┬───────────┬────────┬───────────────┬─────────────┬─────────────┐                                                        ┌─────────────┬─────────────┬──────┬──────┬──────┬─────┬─────┐
//    │          │  M1   │    M2     │   M3   │      M4       │     M5      │     M6      │                                                        │             │             │  M7  │  M8  │  M9  │ M10 │     │
//    ├──────────┼───────┼───────────┼────────┼───────────────┼─────────────┼─────────────┤                                                        ├─────────────┼─────────────┼──────┼──────┼──────┼─────┼─────┤
//    │          │       │ upper M-n │   up   │ kt lsft(lctl) │   restore   │    order    │                                                        │ smart split │  sett_nvim  │ MKP7 │ MKP8 │ MKP9 │     │     │
//    ├──────────┼───────┼───────────┼────────┼───────────────┼─────────────┼─────────────┤              ┌─────┬─────┬───────────┬─────────┐       ├─────────────┼─────────────┼──────┼──────┼──────┼─────┼─────┤
//    │ dwindle  │       │   left    │  down  │     right     │ tog Hypr_gr │ move cursor │              │  &  │  &  │     &     │    &    │       │   swallow   │  dev_nvim   │ MKP4 │ MKP5 │ MKP6 │     │     │
//    ├──────────┼───────┼───────────┼────────┼───────────────┼─────────────┼─────────────┘              └─────┼─────┼───────────┼─────────┘       └─────────────┼─────────────┼──────┼──────┼──────┼─────┼─────┤
//    │ moveroot │       │  resize   │ center │  cls special  │     fit     │                                  │     │ col res + │                               │ trader_nvim │ MKP1 │ MKP2 │ MKP3 │     │  &  │
//    ├──────────┼───────┼───────────┼────────┼───────────────┼─────────────┘             ┌──────────────┬─────┼─────┼───────────┼─────────┬───────┐             └─────────────┼──────┼──────┼──────┼─────┼─────┤
//    │ swap mon │ mon 1 │   mon 2   │        │               │                           │ tog Hyprland │     │     │ col res - │ promote │ MKP10 │                           │      │      │      │     │     │
//    └──────────┴───────┴───────────┴────────┴───────────────┘                           └──────────────┴─────┴─────┴───────────┴─────────┴───────┘                           └──────┴──────┴──────┴─────┴─────┘
      >;
    };
    hypr_gr { 
      display-name = "Hypr group";
      bindings = <
  &none   &kp LG(LS(KP_N1))   &kp LG(LS(KP_N2))          &kp LG(LS(KP_N3))          &kp LG(LS(KP_N4))           &kp LG(LS(KP_N5))   &kp LG(LS(KP_N6))                                                           &none   &none   &none   &none   &none   &none   &none
  &none   &kp LG(LC(G))       &kp LG(LS(KP_N8))          &kp LG(LS(LC(LA(UP))))     &kp LG(LS(KP_N9))           &none               &none                                                                       &none   &none   &none   &none   &none   &none   &none
  &none   &kp LG(LC(LA(G)))   &kp LG(LS(LC(LA(LEFT))))   &kp LG(LS(LC(LA(DOWN))))   &kp LG(LS(LC(LA(RIGHT))))   &tog L_HYPR_GR      &none                               &none   &none   &none   &none           &none   &none   &none   &none   &none   &none   &none
  &none   &kp LG(LS(LA(G)))   &kp LG(LA(G))              &kp LG(LS(LC(G)))          &kp LG(G)                   &none                                                           &none   &none                           &none   &none   &none   &none   &none   &none
  &none   &none               &none                      &none                      &none                                                               &to L_DEFAULT   &none   &none   &none   &none   &none                   &none   &none   &none   &none   &none
//    ┌─────┬────────────┬──────────────┬──────────────┬───────────────┬───────────────┬───────┐                                           ┌─────┬─────┬─────┬─────┬─────┬─────┬─────┐
//    │     │   tab 1    │    tab 2     │    tab 3     │     tab 4     │     tab 5     │ tab 6 │                                           │     │     │     │     │     │     │     │
//    ├─────┼────────────┼──────────────┼──────────────┼───────────────┼───────────────┼───────┤                                           ├─────┼─────┼─────┼─────┼─────┼─────┼─────┤
//    │     │ lock group │ gr move left │    gr up     │ gr move right │               │       │                                           │     │     │     │     │     │     │     │
//    ├─────┼────────────┼──────────────┼──────────────┼───────────────┼───────────────┼───────┤             ┌─────┬─────┬─────┬─────┐     ├─────┼─────┼─────┼─────┼─────┼─────┼─────┤
//    │     │ tgl group  │   gr left    │   gr down    │   gr right    │ tog L_HYPR_GR │       │             │     │     │     │     │     │     │     │     │     │     │     │     │
//    ├─────┼────────────┼──────────────┼──────────────┼───────────────┼───────────────┼───────┘             └─────┼─────┼─────┼─────┘     └─────┼─────┼─────┼─────┼─────┼─────┼─────┤
//    │     │  deny win  │ prev gr tab  │ ignr gr lock │  next gr tab  │               │                           │     │     │                 │     │     │     │     │     │     │
//    ├─────┼────────────┼──────────────┼──────────────┼───────────────┼───────────────┘       ┌─────────────┬─────┼─────┼─────┼─────┬─────┐     └─────┼─────┼─────┼─────┼─────┼─────┤
//    │     │            │              │              │               │                       │ to L_DEFAU< │     │     │     │     │     │           │     │     │     │     │     │
//    └─────┴────────────┴──────────────┴──────────────┴───────────────┘                       └─────────────┴─────┴─────┴─────┴─────┴─────┘           └─────┴─────┴─────┴─────┴─────┘
      >;
    };
    aerospace { 
      display-name = "Aerorpace";
      bindings = <
  &none                                      &kp LG(LC(N1))   &kp LG(LC(N2))                                 &kp LG(LC(N3))     &kp LG(LC(N4))                             &kp LG(LC(N5))      &kp LG(LC(N6))                                                                     &none   &none            &kp LG(LC(N7))   &kp LG(LC(N8))   &kp LG(LC(N9))   &none   &none
  &none                                      &none            &ht_dfn_mfst LG(LS(LA(U))) LG(LS(LC(LA(U))))   &kp LG(LC(UP))     &ht_dfn_mfst LG(LC(LA(U))) LG(LS(LC(U)))   &kp LG(LC(LA(R)))   &none                                                                              &none   &none            &none            &none            &none            &none   &none
  &ht_dfn_mfst LG(LS(LC(J))) LG(LC(LA(J)))   &none            &kp LG(LC(LEFT))                               &kp LG(LC(DOWN))   &kp LG(LC(RIGHT))                          &kp LG(LS(LC(R)))   &kp LG(LS(LA(S)))                      &trans   &trans   &trans   &trans           &none   &kp LG(LC(F1))   &none            &none            &none            &none   &none
  &none                                      &none            &none                                          &none              &none                                      &none                                                               &none    &none                             &none            &none            &none            &none            &none   &trans
  &none                                      &none            &none                                          &none              &none                                                                              &tog L_AEROSPACE   &none    &none    &none    &none    &none                            &none            &none            &none            &none   &none
//    ┌────────┬─────┬─────────────┬──────┬──────────────┬─────────┬─────────┐                                             ┌─────┬──────────┬─────┬─────┬─────┬─────┬─────┐
//    │        │ M1  │     M2      │  M3  │      M4      │   M5    │   M6    │                                             │     │          │ M7  │ M8  │ M9  │     │     │
//    ├────────┼─────┼─────────────┼──────┼──────────────┼─────────┼─────────┤                                             ├─────┼──────────┼─────┼─────┼─────┼─────┼─────┤
//    │        │     │ resize left │  up  │ resize right │ flatten │         │                                             │     │          │     │     │     │     │     │
//    ├────────┼─────┼─────────────┼──────┼──────────────┼─────────┼─────────┤               ┌─────┬─────┬─────┬─────┐     ├─────┼──────────┼─────┼─────┼─────┼─────┼─────┤
//    │ layout │     │    left     │ down │    right     │ balance │ service │               │  &  │  &  │  &  │  &  │     │     │ dev_nvim │     │     │     │     │     │
//    ├────────┼─────┼─────────────┼──────┼──────────────┼─────────┼─────────┘               └─────┼─────┼─────┼─────┘     └─────┼──────────┼─────┼─────┼─────┼─────┼─────┤
//    │        │     │             │      │              │         │                               │     │     │                 │          │     │     │     │     │  &  │
//    ├────────┼─────┼─────────────┼──────┼──────────────┼─────────┘         ┌───────────────┬─────┼─────┼─────┼─────┬─────┐     └──────────┼─────┼─────┼─────┼─────┼─────┤
//    │        │     │             │      │              │                   │ tog Aerospace │     │     │     │     │     │                │     │     │     │     │     │
//    └────────┴─────┴─────────────┴──────┴──────────────┘                   └───────────────┴─────┴─────┴─────┴─────┴─────┘                └─────┴─────┴─────┴─────┴─────┘
      >;
    };
    apps { 
      display-name = "Apps";
      bindings = <
  &kp LG(LS(LC(F8)))   &kp LG(LS(LC(F1)))   &kp LG(LA(F3))   &kp LG(LA(F4))   &kp LG(LS(LA(F5)))   &none                 &kp LG(LA(F7))                                                                     &none   &none   &none   &none   &none   &none   &none
  &none                &kp LG(LS(LC(F2)))   &kp LG(F18)      &kp LG(F21)      &kp LG(F17)          &kp LG(F22)           &kp LG(F23)                                                                        &none   &none   &none   &none   &none   &none   &none
  &kp LG(F1)           &kp LG(F2)           &kp LG(F3)       &kp LG(F4)       &kp LG(F5)           &kp LG(F6)            &kp LG(F7)                        &none            &none   &none   &none           &none   &none   &none   &none   &none   &none   &none
  &kp LG(F8)           &kp LG(F13)          &kp LG(F10)      &kp LG(F11)      &kp LG(F12)          &kp LG(LS(LC(F12)))                                                      &none   &none                           &none   &none   &none   &none   &none   &none
  &kp LG(LC(LA(H)))    &kp LG(F9)           &kp LG(F14)      &kp LG(F15)      &kp LG(F16)                                                 &kp LG(LA(F8))   &kp LG(LA(F1))   &none   &none   &none   &none                   &none   &none   &none   &none   &none
//    ┌─────────────┬────────────┬───────────┬───────────────┬──────────┬─────────────────┬─────────────┐                                         ┌─────┬─────┬─────┬─────┬─────┬─────┬─────┐
//    │  Files nw   │ Sublime nw │  Photos   │   Capture1    │ Davinci  │                 │    Music    │                                         │     │     │     │     │     │     │     │
//    ├─────────────┼────────────┼───────────┼───────────────┼──────────┼─────────────────┼─────────────┤                                         ├─────┼─────┼─────┼─────┼─────┼─────┼─────┤
//    │             │ VSConed nw │   Word    │     Excel     │ Obsidian │       ZIP       │ Sys monitor │                                         │     │     │     │     │     │     │     │
//    ├─────────────┼────────────┼───────────┼───────────────┼──────────┼─────────────────┼─────────────┤      ┌──────────┬─────┬─────┬─────┐     ├─────┼─────┼─────┼─────┼─────┼─────┼─────┤
//    │   Sublime   │   VSCode   │ WebStorm  │    PyCharm    │  Clion   │    Datagrip     │  Password   │      │          │     │     │     │     │     │     │     │     │     │     │     │
//    ├─────────────┼────────────┼───────────┼───────────────┼──────────┼─────────────────┼─────────────┘      └──────────┼─────┼─────┼─────┘     └─────┼─────┼─────┼─────┼─────┼─────┼─────┤
//    │    Files    │    RDP     │ Tor/Notes │ Chrome/Remdrs │ Browser  │ Browser nw/Calc │                               │     │     │                 │     │     │     │     │     │     │
//    ├─────────────┼────────────┼───────────┼───────────────┼──────────┼─────────────────┘             ┌──────┬──────────┼─────┼─────┼─────┬─────┐     └─────┼─────┼─────┼─────┼─────┼─────┤
//    │ cls special │    Mail    │  Player   │  Transl/Mon   │ Telegram │                               │ Yazi │ Terminal │     │     │     │     │           │     │     │     │     │     │
//    └─────────────┴────────────┴───────────┴───────────────┴──────────┘                               └──────┴──────────┴─────┴─────┴─────┴─────┘           └─────┴─────┴─────┴─────┴─────┘
      >;
    };
    editor { 
      display-name = "Editor";
      bindings = <
  &kp LC(F9)                             &ht_dfn_mfst LC(LA(COMMA)) LA(COMMA)   &ht_dfn_mfst LS(LC(LA(F9))) F9     &kp F8                            &ht_dfn_mfst LS(F8) F7   &td_breakpoint                               &ht_dfn_mfst LS(LC(LA(F4))) LS(LC(LA(F3)))                                                                                                            &kp LS(LC(LA(R)))   &kp LS(LC(LA(Q)))                                  &none                   &none                &none                                      &none               &none
  &ht_dfn_mfst LS(LC(LA(G))) LS(LC(G))   &kp LC(F12)                            &kp LA(INSERT)                     &td_e_methods                     &td_e_refactor           &ht_dfn_mfst LS(LC(SEMI)) LS(LC(LA(SEMI)))   &kp LS(LA(U))                                                                                                                                         &kp LS(LC(LA(Y)))   &ht_dfn_mfst LS(LA(G)) LS(LA(INSERT))              &kp LC(K)               &kp LC(LA(Z))        &ht_dfn_mfst LS(LC(LA(K))) LS(LC(LA(E)))   &kp LS(LA(K))       &none
  &kp LS(LC(M))                          &td_e_sur_life                         &ht_dfn_mfst LS(ESC) LS(LC(F12))   &ht_dfn_mfst LA(Y) LS(LC(BSPC))   &kp LC(LA(L))            &td_e_bookmarks                              &ht_dfn_mfst LS(LA(DOT)) LS(LA(COMMA))                &ht_dfn_mfst LS(LA(F9)) LS(F9)         &kp LC(F2)   &none   &kp LC(LA(S))                       &kp LS(LC(LA(S)))   &ht_dfn_mfst LS(LC(LA(MINUS))) LS(LC(LA(EQUAL)))   &kp LS(LC(LA(COMMA)))   &kp LS(LC(LA(F1)))   &kp LS(LC(COMMA))                          &kp LS(LC(F1))      &none
  &kp LS(LC(I))                          &kp LA(LEFT_BRACKET)                   &kp F4                             &kp LA(F1)                        &kp LS(LC(SLASH))        &ht_dfn_mfst LS(LC(LA(INSERT))) LA(INSERT)                                                                                                &none        &none                                                           &kp LS(LA(SEMI))                                   &td_e_f_expand          &td_e_f_collapse     &kp LS(LC(LA(DOT)))                        &kp LS(LC(LA(P)))   &none
  &kp LS(LC(LA(O)))                      &kp LS(LC(LA(C)))                      &kp LS(LC(LA(Z)))                  &kp LC(Y)                         &kp LC(SLASH)                                                                                                      &kp F5   &ht_dfn_mfst LS(LC(LA(F10))) LS(F10)   &none        &none   &none           &kp LS(LC(GRAVE))                                                                          &none                   &none                &none                                      &none               &none
//    ┌───────────────┬─────────────────┬─────────────────┬───────────┬───────────────┬─────────────┬────────────────┐                                                ┌───────────┬────────────┬─────────────────┬───────────────────┬───────────────┬───────────┬─────┐
//    │     build     │      cmake      │       run       │    f8     │   step into   │ breakpoint  │ del breakpoint │                                                │   exit    │ close proj │                 │                   │               │           │     │
//    ├───────────────┼─────────────────┼─────────────────┼───────────┼───────────────┼─────────────┼────────────────┤                                                ├───────────┼────────────┼─────────────────┼───────────────────┼───────────────┼───────────┼─────┤
//    │   splitter    │   file struct   │    generate     │  method   │   refactor    │ clone caret │  toggle case   │                                                │    vim    │   carets   │   git commit    │   git rollback    │ git diff/hist │ submit db │     │
//    ├───────────────┼─────────────────┼─────────────────┼───────────┼───────────────┼─────────────┼────────────────┤    ┌───────┬──────┬─────┬──────────┐           ├───────────┼────────────┼─────────────────┼───────────────────┼───────────────┼───────────┼─────┤
//    │ match bracket │ surround/live t │  hide toolbars  │ edit loc  │   reformat    │  bookmarks  │   scroll to    │    │ debug │ stop │     │ settings │           │ soft wrap │ font size  │ mouse & scrl up │ mouse & scrl down │    scrl up    │ scrl down │     │
//    ├───────────────┼─────────────────┼─────────────────┼───────────┼───────────────┼─────────────┼────────────────┘    └───────┼──────┼─────┼──────────┘           └───────────┼────────────┼─────────────────┼───────────────────┼───────────────┼───────────┼─────┤
//    │   quick def   │   find usage    │       f4        │ select in │ block comment │ scratch/new │                             │      │     │                                  │ compare f  │   fold expand   │   fold collapse   │  fold select  │  extend   │     │
//    ├───────────────┼─────────────────┼─────────────────┼───────────┼───────────────┼─────────────┘                ┌────┬───────┼──────┼─────┼──────────┬───────────┐           └────────────┼─────────────────┼───────────────────┼───────────────┼───────────┼─────┤
//    │  hidden tabs  │    copy path    │ reop closed tab │ del line  │    comment    │                              │ f5 │  run  │      │     │          │ edit conf │                        │                 │                   │               │           │     │
//    └───────────────┴─────────────────┴─────────────────┴───────────┴───────────────┘                              └────┴───────┴──────┴─────┴──────────┴───────────┘                        └─────────────────┴───────────────────┴───────────────┴───────────┴─────┘
      >;
    };
  };
  
  // Input processors
  input_processors {
    turbo_scroll_scaler: turbo_scroll_scaler {
            compatible = "zmk,input-processor-scaler";
            #input-processor-cells = <2>;
            type = <INPUT_EV_REL>;
            codes = <INPUT_REL_WHEEL INPUT_REL_HWHEEL>;
            track-remainders;
        };
    };
};

// Listeners
&mmv_input_listener {
    turbo_cursor {
        layers = <L_MOUSE_TRB>;
        input-processors = <&zip_xy_scaler 7 2>;
    };
};
&msc_input_listener {
    turbo_scroll {
        layers = <L_MOUSE_TRB>;
        input-processors = <&turbo_scroll_scaler 4 1>;
    };
};
